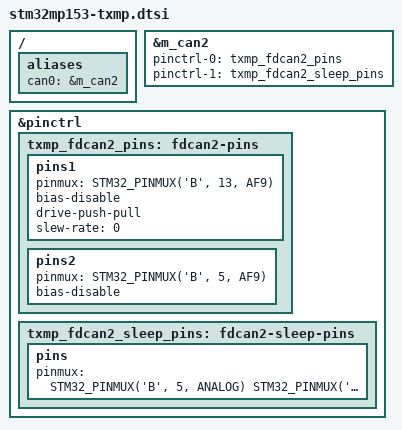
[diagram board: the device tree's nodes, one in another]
// SPDX-License-Identifier: (GPL-2.0 OR BSD-3-Clause)
/*
 * Copyright (C) Lothar Waßmann <LW@KARO-electronics.de>
 */

#include "stm32mp15-txmp.dtsi"
#include "stm32mp153-karo.dtsi"

/ {
	aliases {
		can0 = &m_can2;
	};
};

&m_can2 {
	pinctrl-names = "default", "sleep";
	pinctrl-0 = <&txmp_fdcan2_pins>;
	pinctrl-1 = <&txmp_fdcan2_sleep_pins>;
	status = "okay";
};

&pinctrl {
	txmp_fdcan2_pins: fdcan2-pins {
		pins1 {
			pinmux = <STM32_PINMUX('B', 13, AF9)>; /* FDCAN2_TX */
			bias-disable;
			drive-push-pull;
			slew-rate = <0>;
		};

		pins2 {
			pinmux = <STM32_PINMUX('B', 5, AF9)>; /* FDCAN2_RX */
			bias-disable;
		};
	};

	txmp_fdcan2_sleep_pins: fdcan2-sleep-pins {
		pins {
			pinmux = <
				  STM32_PINMUX('B', 5, ANALOG) /* FDCAN2_RX */
				  STM32_PINMUX('B', 13, ANALOG) /* FDCAN2_TX */
			>;
		};
	};
};
